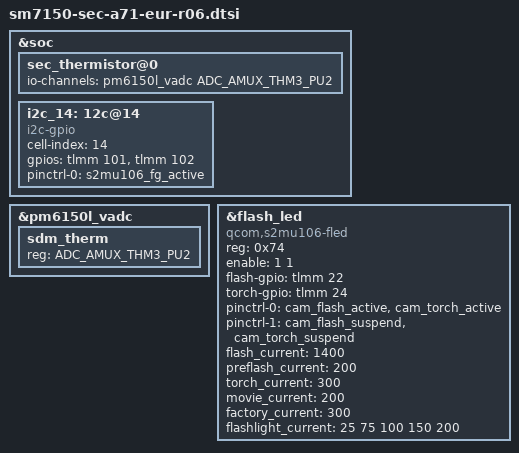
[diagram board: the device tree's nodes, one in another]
/* Copyright (c) 2019, The Linux Foundation. All rights reserved. 

* 

* This program is free software; you can redistribute it and/or modify 

* it under the terms of the GNU General Public License version 2 and 

* only version 2 as published by the Free Software Foundation. 

* 

* This program is distributed in the hope that it will be useful, 

* but WITHOUT ANY WARRANTY; without even the implied warranty of 

* MERCHANTABILITY or FITNESS FOR A PARTICULAR PURPOSE.  See the 

* GNU General Public License for more details. 

*/ 


#include "sm7150-sec-a71-eur-pinctrl-r00.dtsi"
#include "sm7150-sec-a71-eur-pinctrl-r01.dtsi"
#include "sm7150-sec-a71-eur-pinctrl-r02.dtsi"
#include "sm7150-sec-a71-eur-pinctrl-r03.dtsi"
#include "sm7150-sec-a71-eur-pinctrl-r04.dtsi"
#include "sm7150-sec-a71-eur-pinctrl-r05.dtsi"
#include "sm7150-sec-a71-eur-pinctrl-r06.dtsi"

#include "../common/sm7150-sec-a71-common.dtsi"
// #include "sm6150-sec-a70q-input-common.dtsi"
#include "../common/sm7150-sec-a71-pm-common.dtsi"
#include "../common/sm7150-sec-a71-battery-common.dtsi"
#include "../drivers/sm7150-sec-a71-eif-common.dtsi"
#include "../drivers/sm7150-sec-a71-fingerprint_00.dtsi"
#include "../drivers/sm7150-sec-a71-nfc-r00.dtsi"
#include "../drivers/sm7150-camera-sensor-a71-r01.dtsi"
//#include "../drivers/sm7150-sec-a71-display-r00.dtsi"


&soc {
	sec_thermistor@0 {
		io-channels = <&pm6150l_vadc ADC_AMUX_THM3_PU2>;
	};

	i2c_14: 12c@14 {
		status  = "ok";

		cell-index = <14>;
		compatible = "i2c-gpio";
		gpios = <&tlmm 101 0 /*sda*/
			&tlmm 102 0 /*scl*/
			>;

		#address-cells = <1>;
		#size-cells = <0>;
		pinctrl-names = "default";
		pinctrl-0 = <&s2mu106_fg_active>;
	};
};

&pm6150l_vadc {
	sdm_therm {
		reg = <ADC_AMUX_THM3_PU2>;
	};
};

&flash_led {
	reg = <0x74>;
	compatible = "qcom,s2mu106-fled";
	enable = <1 1>;
	flash-gpio = <&tlmm 22 0>;
	torch-gpio = <&tlmm 24 0>;
	pinctrl-names = "fled_default", "fled_suspend";
	pinctrl-0 = <&cam_flash_active &cam_torch_active>;
	pinctrl-1 = <&cam_flash_suspend &cam_torch_suspend>;
	flash_current = <1400>;
	preflash_current = <200>;
	torch_current = <300>;
	movie_current = <200>;
	factory_current = <300>;
	flashlight_current = <25 75 100 150 200>;
	status = "okay";
};
